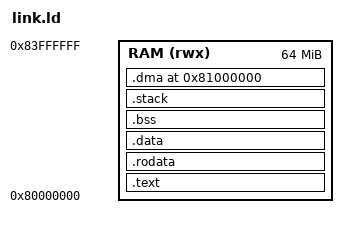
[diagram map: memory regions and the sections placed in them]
/*
 * Copyright (c) 2026 Roman Popov
 * SPDX-License-Identifier: BSD-3-Clause
 */
OUTPUT_ARCH(riscv)
ENTRY(_start)
MEMORY { RAM (rwx) : ORIGIN = 0x80000000, LENGTH = 64M }
SECTIONS
{
    .text : { KEEP(*(.text.init)) *(.text .text.*) } > RAM
    .rodata : { *(.rodata .rodata.*) } > RAM
    .data : {
        *(.data .data.*)
        PROVIDE(__global_pointer$ = . + 0x800);
        *(.sdata .sdata.*)
    } > RAM
    .bss (NOLOAD) : {
        . = ALIGN(8);
        __bss_start = .;
        *(.sbss .sbss.* .bss .bss.*) *(COMMON)
        . = ALIGN(8);
        __bss_end = .;
    } > RAM
    .stack (NOLOAD) : {
        . = ALIGN(16);
        . += 16384;
        __stack_top = .;
    } > RAM
    .dma 0x81000000 (NOLOAD) : { *(.dma) } > RAM
    ASSERT(__stack_top - ORIGIN(RAM) <= 262144,
           "Firmware including host buffers exceeds 256 KiB")
}
